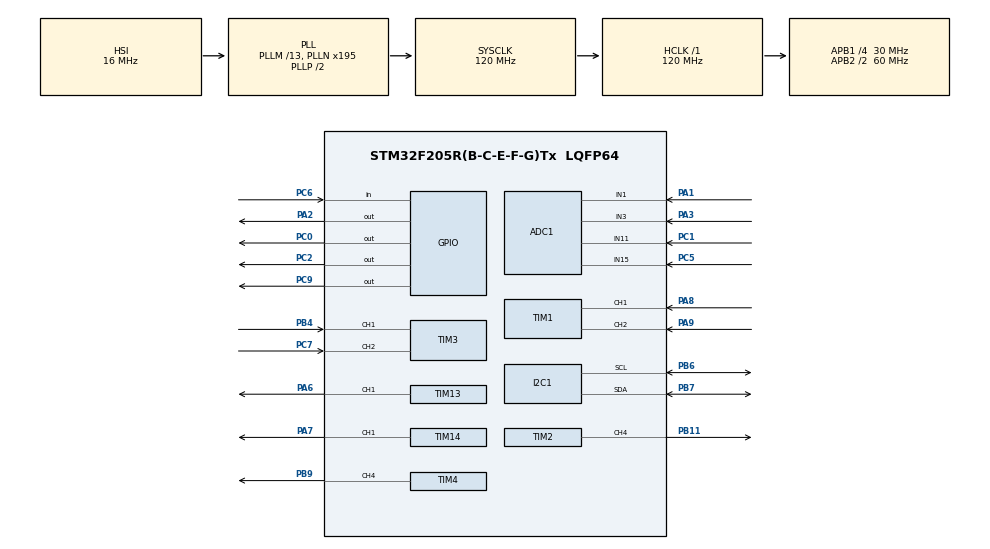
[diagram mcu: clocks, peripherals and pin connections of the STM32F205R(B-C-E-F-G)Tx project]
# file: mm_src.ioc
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ADC1.Channel-0\#ChannelRegularConversion=ADC_CHANNEL_11
ADC1.Channel-1\#ChannelRegularConversion=ADC_CHANNEL_1
ADC1.Channel-2\#ChannelRegularConversion=ADC_CHANNEL_15
ADC1.ContinuousConvMode=ENABLE
ADC1.NbrOfConversion=3
ADC1.NbrOfConversionFlag=1
ADC1.Rank-0\#ChannelRegularConversion=1
ADC1.Rank-1\#ChannelRegularConversion=2
ADC1.Rank-2\#ChannelRegularConversion=3
ADC1.SamplingTime-0\#ChannelRegularConversion=ADC_SAMPLETIME_3CYCLES
ADC1.SamplingTime-1\#ChannelRegularConversion=ADC_SAMPLETIME_3CYCLES
ADC1.SamplingTime-2\#ChannelRegularConversion=ADC_SAMPLETIME_3CYCLES
ADC1.ScanConvMode=ENABLE
ADC1.master=1
Dma.ADC1.0.Direction=DMA_PERIPH_TO_MEMORY
Dma.ADC1.0.FIFOMode=DMA_FIFOMODE_DISABLE
Dma.ADC1.0.Instance=DMA2_Stream0
Dma.ADC1.0.MemDataAlignment=DMA_MDATAALIGN_WORD
Dma.ADC1.0.MemInc=DMA_MINC_ENABLE
Dma.ADC1.0.Mode=DMA_CIRCULAR
Dma.ADC1.0.PeriphDataAlignment=DMA_PDATAALIGN_WORD
Dma.ADC1.0.PeriphInc=DMA_PINC_DISABLE
Dma.ADC1.0.Priority=DMA_PRIORITY_LOW
Dma.Request0=ADC1
Mcu.Family=STM32F2
Mcu.Name=STM32F205R(B-C-E-F-G)Tx
Mcu.Package=LQFP64
NVIC.DMA2_Stream0_IRQn=true\:0\:0\:false\:false\:true\:false\:true\:true
NVIC.PriorityGroup=NVIC_PRIORITYGROUP_4
PA1.Signal=ADCx_IN1
PA13.Mode=Serial_Wire
PA13.Signal=SYS_JTMS-SWDIO
PA14.Mode=Serial_Wire
PA14.Signal=SYS_JTCK-SWCLK
PA2.Signal=GPIO_Output
PA3.Signal=ADCx_IN3
PA6.Signal=S_TIM13_CH1
PA7.Signal=S_TIM14_CH1
PA8.Signal=S_TIM1_CH1
PA9.Signal=S_TIM1_CH2
PB11.Signal=S_TIM2_CH4
PB4.Signal=S_TIM3_CH1
PB6.Mode=I2C
PB6.Signal=I2C1_SCL
PB7.Mode=I2C
PB7.Signal=I2C1_SDA
PB9.Signal=S_TIM4_CH4
PC0.Signal=GPIO_Output
PC1.Signal=ADCx_IN11
PC2.Signal=GPIO_Output
PC5.Signal=ADCx_IN15
PC6.Signal=GPIO_Input
PC7.Signal=S_TIM3_CH2
PC9.Signal=GPIO_Output
PH0-OSC_IN.Mode=HSE-External-Oscillator
PH0-OSC_IN.Signal=RCC_OSC_IN
PH1-OSC_OUT.Mode=HSE-External-Oscillator
PH1-OSC_OUT.Signal=RCC_OSC_OUT
ProjectManager.HeapSize=0x200
ProjectManager.StackSize=0x400
ProjectManager.TargetToolchain=STM32CubeIDE
RCC.48MHZClocksFreq_Value=60000000
RCC.AHBFreq_Value=120000000
RCC.APB1CLKDivider=RCC_HCLK_DIV4
RCC.APB1Freq_Value=30000000
RCC.APB1TimFreq_Value=60000000
RCC.APB2CLKDivider=RCC_HCLK_DIV2
RCC.APB2Freq_Value=60000000
RCC.APB2TimFreq_Value=120000000
RCC.CortexFreq_Value=120000000
RCC.HCLKFreq_Value=120000000
RCC.HSE_VALUE=25000000
RCC.HSI_VALUE=16000000
RCC.LSE_VALUE=32768
RCC.PLLM=13
RCC.PLLN=195
RCC.SYSCLKFreq_VALUE=120000000
RCC.SYSCLKSource=RCC_SYSCLKSOURCE_PLLCLK
RCC.VCOOutputFreq_Value=240000000
SH.ADCx_IN1.0=ADC1_IN1,IN1
SH.ADCx_IN11.0=ADC1_IN11,IN11
SH.ADCx_IN15.0=ADC1_IN15,IN15
SH.ADCx_IN3.0=ADC1_IN3,IN3
SH.S_TIM13_CH1.0=TIM13_CH1,PWM Generation1 CH1
SH.S_TIM14_CH1.0=TIM14_CH1,PWM Generation1 CH1
SH.S_TIM1_CH1.0=TIM1_CH1,Encoder_Interface
SH.S_TIM1_CH2.0=TIM1_CH2,Encoder_Interface
SH.S_TIM2_CH4.0=TIM2_CH4,PWM Generation4 CH4
SH.S_TIM3_CH1.0=TIM3_CH1,Encoder_Interface
SH.S_TIM3_CH2.0=TIM3_CH2,Encoder_Interface
SH.S_TIM4_CH4.0=TIM4_CH4,PWM Generation4 CH4
TIM13.Channel=TIM_CHANNEL_1
TIM13.Period=1000-1
TIM13.Prescaler=120-1
TIM14.Channel=TIM_CHANNEL_1
TIM14.Period=1000-1
TIM14.Prescaler=120-1
TIM2.AutoReloadPreload=TIM_AUTORELOAD_PRELOAD_ENABLE
TIM2.Channel-PWM\ Generation4\ CH4=TIM_CHANNEL_4
TIM2.Period=1000-1
TIM2.Prescaler=120-1
TIM4.AutoReloadPreload=TIM_AUTORELOAD_PRELOAD_ENABLE
TIM4.Channel-PWM\ Generation4\ CH4=TIM_CHANNEL_4
TIM4.Period=1000-1
TIM4.Prescaler=120-1
VP_TIM13_VS_ClockSourceINT.Mode=Enable_Timer
VP_TIM14_VS_ClockSourceINT.Mode=Enable_Timer
board=custom

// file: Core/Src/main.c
/* USER CODE BEGIN Header */
/**
 ******************************************************************************
 * @file           : main.c
 * @brief          : Main program body
 ******************************************************************************
 * @attention
 *
 * Copyright (c) 2026 STMicroelectronics.
 * All rights reserved.
 *
 * This software is licensed under terms that can be found in the LICENSE file
 * in the root directory of this software component.
 * If no LICENSE file comes with this software, it is provided AS-IS.
 *
 ******************************************************************************
 */
/* USER CODE END Header */
#include "main.h"

/* USER CODE BEGIN Includes */
#include <stdlib.h>
#include "stm32f2xx_hal.h"
#include "motors.h"
#include "sensors.h"
#include "global_c.h"
/* USER CODE END Includes */

ADC_HandleTypeDef hadc1;
DMA_HandleTypeDef hdma_adc1;

I2C_HandleTypeDef hi2c1;

TIM_HandleTypeDef htim1;
TIM_HandleTypeDef htim2;
TIM_HandleTypeDef htim3;
TIM_HandleTypeDef htim4;
TIM_HandleTypeDef htim13;
TIM_HandleTypeDef htim14;

void SystemClock_Config(void);
static void MX_GPIO_Init(void);
static void MX_DMA_Init(void);
static void MX_ADC1_Init(void);
static void MX_TIM2_Init(void);
static void MX_TIM3_Init(void);
static void MX_TIM4_Init(void);
static void MX_I2C1_Init(void);
static void MX_TIM1_Init(void);
static void MX_TIM13_Init(void);
static void MX_TIM14_Init(void);

int main(void) {

	/* MCU Configuration--------------------------------------------------------*/

	/* Reset of all peripherals, Initializes the Flash interface and the Systick. */
	HAL_Init();

	/* USER CODE BEGIN Init */
	Motor_Init();
	/* USER CODE END Init */

	/* Configure the system clock */
	SystemClock_Config();

	/* Initialize all configured peripherals */
	MX_GPIO_Init();
	MX_DMA_Init();
	MX_ADC1_Init();
	MX_TIM2_Init();
	MX_TIM3_Init();
	MX_TIM4_Init();
	MX_I2C1_Init();
	MX_TIM1_Init();
	MX_TIM13_Init();
	MX_TIM14_Init();

	/* Infinite loop */
	while (1) {
		IR_EmittersOn();
		HAL_Delay(1);
		// adc_buf gets read by DMA automatically
		IR_EmittersOff();
		HAL_Delay(10);
	}
}

void SystemClock_Config(void) {
	RCC_OscInitTypeDef RCC_OscInitStruct = { 0 };
	RCC_ClkInitTypeDef RCC_ClkInitStruct = { 0 };

	/** Initializes the RCC Oscillators according to the specified parameters
	 * in the RCC_OscInitTypeDef structure.
	 */
	RCC_OscInitStruct.OscillatorType = RCC_OSCILLATORTYPE_HSI;
	RCC_OscInitStruct.HSIState = RCC_HSI_ON;
	RCC_OscInitStruct.HSICalibrationValue = RCC_HSICALIBRATION_DEFAULT;
	RCC_OscInitStruct.PLL.PLLState = RCC_PLL_ON;
	RCC_OscInitStruct.PLL.PLLSource = RCC_PLLSOURCE_HSI;
	RCC_OscInitStruct.PLL.PLLM = 13;
	RCC_OscInitStruct.PLL.PLLN = 195;
	RCC_OscInitStruct.PLL.PLLP = RCC_PLLP_DIV2;
	RCC_OscInitStruct.PLL.PLLQ = 4;
	if (HAL_RCC_OscConfig(&RCC_OscInitStruct) != HAL_OK) {
		Error_Handler();
	}

	/** Initializes the CPU, AHB and APB buses clocks
	 */
	RCC_ClkInitStruct.ClockType = RCC_CLOCKTYPE_HCLK | RCC_CLOCKTYPE_SYSCLK
			| RCC_CLOCKTYPE_PCLK1 | RCC_CLOCKTYPE_PCLK2;
	RCC_ClkInitStruct.SYSCLKSource = RCC_SYSCLKSOURCE_PLLCLK;
	RCC_ClkInitStruct.AHBCLKDivider = RCC_SYSCLK_DIV1;
	RCC_ClkInitStruct.APB1CLKDivider = RCC_HCLK_DIV4;
	RCC_ClkInitStruct.APB2CLKDivider = RCC_HCLK_DIV2;

	if (HAL_RCC_ClockConfig(&RCC_ClkInitStruct, FLASH_LATENCY_3) != HAL_OK) {
		Error_Handler();
	}
}

static void MX_ADC1_Init(void) {

	ADC_ChannelConfTypeDef sConfig = { 0 };

	/** Configure the global features of the ADC (Clock, Resolution, Data Alignment and number of conversion)
	 */
	hadc1.Instance = ADC1;
	hadc1.Init.ClockPrescaler = ADC_CLOCK_SYNC_PCLK_DIV2;
	hadc1.Init.Resolution = ADC_RESOLUTION_12B;
	hadc1.Init.ScanConvMode = ENABLE;
	hadc1.Init.ContinuousConvMode = ENABLE;
	hadc1.Init.DiscontinuousConvMode = DISABLE;
	hadc1.Init.ExternalTrigConvEdge = ADC_EXTERNALTRIGCONVEDGE_NONE;
	hadc1.Init.ExternalTrigConv = ADC_SOFTWARE_START;
	hadc1.Init.DataAlign = ADC_DATAALIGN_RIGHT;
	hadc1.Init.NbrOfConversion = 3;
	hadc1.Init.DMAContinuousRequests = DISABLE;
	hadc1.Init.EOCSelection = ADC_EOC_SINGLE_CONV;
	if (HAL_ADC_Init(&hadc1) != HAL_OK) {
		Error_Handler();
	}

	/** Configure for the selected ADC regular channel its corresponding rank in the sequencer and its sample time.
	 */
	sConfig.Channel = ADC_CHANNEL_11;
	sConfig.Rank = 1;
	sConfig.SamplingTime = ADC_SAMPLETIME_3CYCLES;
	if (HAL_ADC_ConfigChannel(&hadc1, &sConfig) != HAL_OK) {
		Error_Handler();
	}

	/** Configure for the selected ADC regular channel its corresponding rank in the sequencer and its sample time.
	 */
	sConfig.Channel = ADC_CHANNEL_1;
	sConfig.Rank = 2;
	if (HAL_ADC_ConfigChannel(&hadc1, &sConfig) != HAL_OK) {
		Error_Handler();
	}

	/** Configure for the selected ADC regular channel its corresponding rank in the sequencer and its sample time.
	 */
	sConfig.Channel = ADC_CHANNEL_15;
	sConfig.Rank = 3;
	if (HAL_ADC_ConfigChannel(&hadc1, &sConfig) != HAL_OK) {
		Error_Handler();
	}

}

static void MX_I2C1_Init(void) {

	hi2c1.Instance = I2C1;
	hi2c1.Init.ClockSpeed = 100000;
	hi2c1.Init.DutyCycle = I2C_DUTYCYCLE_2;
	hi2c1.Init.OwnAddress1 = 0;
	hi2c1.Init.AddressingMode = I2C_ADDRESSINGMODE_7BIT;
	hi2c1.Init.DualAddressMode = I2C_DUALADDRESS_DISABLE;
	hi2c1.Init.OwnAddress2 = 0;
	hi2c1.Init.GeneralCallMode = I2C_GENERALCALL_DISABLE;
	hi2c1.Init.NoStretchMode = I2C_NOSTRETCH_DISABLE;
	if (HAL_I2C_Init(&hi2c1) != HAL_OK) {
		Error_Handler();
	}

}

static void MX_TIM1_Init(void) {

	TIM_Encoder_InitTypeDef sConfig = { 0 };
	TIM_MasterConfigTypeDef sMasterConfig = { 0 };

	htim1.Instance = TIM1;
	htim1.Init.Prescaler = 0;
	htim1.Init.CounterMode = TIM_COUNTERMODE_UP;
	htim1.Init.Period = 65535;
	htim1.Init.ClockDivision = TIM_CLOCKDIVISION_DIV1;
	htim1.Init.RepetitionCounter = 0;
	htim1.Init.AutoReloadPreload = TIM_AUTORELOAD_PRELOAD_DISABLE;
	sConfig.EncoderMode = TIM_ENCODERMODE_TI1;
	sConfig.IC1Polarity = TIM_ICPOLARITY_RISING;
	sConfig.IC1Selection = TIM_ICSELECTION_DIRECTTI;
	sConfig.IC1Prescaler = TIM_ICPSC_DIV1;
	sConfig.IC1Filter = 0;
	sConfig.IC2Polarity = TIM_ICPOLARITY_RISING;
	sConfig.IC2Selection = TIM_ICSELECTION_DIRECTTI;
	sConfig.IC2Prescaler = TIM_ICPSC_DIV1;
	sConfig.IC2Filter = 0;
	if (HAL_TIM_Encoder_Init(&htim1, &sConfig) != HAL_OK) {
		Error_Handler();
	}
	sMasterConfig.MasterOutputTrigger = TIM_TRGO_RESET;
	sMasterConfig.MasterSlaveMode = TIM_MASTERSLAVEMODE_DISABLE;
	if (HAL_TIMEx_MasterConfigSynchronization(&htim1, &sMasterConfig)
			!= HAL_OK) {
		Error_Handler();
	}

}

static void MX_TIM2_Init(void) {

	TIM_MasterConfigTypeDef sMasterConfig = { 0 };
	TIM_OC_InitTypeDef sConfigOC = { 0 };

	htim2.Instance = TIM2;
	htim2.Init.Prescaler = 120 - 1;
	htim2.Init.CounterMode = TIM_COUNTERMODE_UP;
	htim2.Init.Period = 1000 - 1;
	htim2.Init.ClockDivision = TIM_CLOCKDIVISION_DIV1;
	htim2.Init.AutoReloadPreload = TIM_AUTORELOAD_PRELOAD_ENABLE;
	if (HAL_TIM_PWM_Init(&htim2) != HAL_OK) {
		Error_Handler();
	}
	sMasterConfig.MasterOutputTrigger = TIM_TRGO_RESET;
	sMasterConfig.MasterSlaveMode = TIM_MASTERSLAVEMODE_DISABLE;
	if (HAL_TIMEx_MasterConfigSynchronization(&htim2, &sMasterConfig)
			!= HAL_OK) {
		Error_Handler();
	}
	sConfigOC.OCMode = TIM_OCMODE_PWM1;
	sConfigOC.Pulse = 0;
	sConfigOC.OCPolarity = TIM_OCPOLARITY_HIGH;
	sConfigOC.OCFastMode = TIM_OCFAST_DISABLE;
	if (HAL_TIM_PWM_ConfigChannel(&htim2, &sConfigOC, TIM_CHANNEL_4)
			!= HAL_OK) {
		Error_Handler();
	}
	HAL_TIM_MspPostInit(&htim2);

}

static void MX_TIM3_Init(void) {

	TIM_Encoder_InitTypeDef sConfig = { 0 };
	TIM_MasterConfigTypeDef sMasterConfig = { 0 };

	htim3.Instance = TIM3;
	htim3.Init.Prescaler = 0;
	htim3.Init.CounterMode = TIM_COUNTERMODE_UP;
	htim3.Init.Period = 65535;
	htim3.Init.ClockDivision = TIM_CLOCKDIVISION_DIV1;
	htim3.Init.AutoReloadPreload = TIM_AUTORELOAD_PRELOAD_DISABLE;
	sConfig.EncoderMode = TIM_ENCODERMODE_TI1;
	sConfig.IC1Polarity = TIM_ICPOLARITY_RISING;
	sConfig.IC1Selection = TIM_ICSELECTION_DIRECTTI;
	sConfig.IC1Prescaler = TIM_ICPSC_DIV1;
	sConfig.IC1Filter = 0;
	sConfig.IC2Polarity = TIM_ICPOLARITY_RISING;
	sConfig.IC2Selection = TIM_ICSELECTION_DIRECTTI;
	sConfig.IC2Prescaler = TIM_ICPSC_DIV1;
	sConfig.IC2Filter = 0;
	if (HAL_TIM_Encoder_Init(&htim3, &sConfig) != HAL_OK) {
		Error_Handler();
	}
	sMasterConfig.MasterOutputTrigger = TIM_TRGO_RESET;
	sMasterConfig.MasterSlaveMode = TIM_MASTERSLAVEMODE_DISABLE;
	if (HAL_TIMEx_MasterConfigSynchronization(&htim3, &sMasterConfig)
			!= HAL_OK) {
		Error_Handler();
	}

}

static void MX_TIM4_Init(void) {

	TIM_MasterConfigTypeDef sMasterConfig = { 0 };
	TIM_OC_InitTypeDef sConfigOC = { 0 };

	htim4.Instance = TIM4;
	htim4.Init.Prescaler = 120 - 1;
	htim4.Init.CounterMode = TIM_COUNTERMODE_UP;
	htim4.Init.Period = 1000 - 1;
	htim4.Init.ClockDivision = TIM_CLOCKDIVISION_DIV1;
	htim4.Init.AutoReloadPreload = TIM_AUTORELOAD_PRELOAD_ENABLE;
	if (HAL_TIM_PWM_Init(&htim4) != HAL_OK) {
		Error_Handler();
	}
	sMasterConfig.MasterOutputTrigger = TIM_TRGO_RESET;
	sMasterConfig.MasterSlaveMode = TIM_MASTERSLAVEMODE_DISABLE;
	if (HAL_TIMEx_MasterConfigSynchronization(&htim4, &sMasterConfig)
			!= HAL_OK) {
		Error_Handler();
	}
	sConfigOC.OCMode = TIM_OCMODE_PWM1;
	sConfigOC.Pulse = 0;
	sConfigOC.OCPolarity = TIM_OCPOLARITY_HIGH;
	sConfigOC.OCFastMode = TIM_OCFAST_DISABLE;
	if (HAL_TIM_PWM_ConfigChannel(&htim4, &sConfigOC, TIM_CHANNEL_4)
			!= HAL_OK) {
		Error_Handler();
	}
	HAL_TIM_MspPostInit(&htim4);

}

static void MX_TIM13_Init(void) {

	TIM_OC_InitTypeDef sConfigOC = { 0 };

	htim13.Instance = TIM13;
	htim13.Init.Prescaler = 120 - 1;
	htim13.Init.CounterMode = TIM_COUNTERMODE_UP;
	htim13.Init.Period = 1000 - 1;
	htim13.Init.ClockDivision = TIM_CLOCKDIVISION_DIV1;
	htim13.Init.AutoReloadPreload = TIM_AUTORELOAD_PRELOAD_DISABLE;
	if (HAL_TIM_Base_Init(&htim13) != HAL_OK) {
		Error_Handler();
	}
	if (HAL_TIM_PWM_Init(&htim13) != HAL_OK) {
		Error_Handler();
	}
	sConfigOC.OCMode = TIM_OCMODE_PWM1;
	sConfigOC.Pulse = 0;
	sConfigOC.OCPolarity = TIM_OCPOLARITY_HIGH;
	sConfigOC.OCFastMode = TIM_OCFAST_DISABLE;
	if (HAL_TIM_PWM_ConfigChannel(&htim13, &sConfigOC, TIM_CHANNEL_1)
			!= HAL_OK) {
		Error_Handler();
	}
	HAL_TIM_MspPostInit(&htim13);

}

static void MX_TIM14_Init(void) {

	TIM_OC_InitTypeDef sConfigOC = { 0 };

	htim14.Instance = TIM14;
	htim14.Init.Prescaler = 120 - 1;
	htim14.Init.CounterMode = TIM_COUNTERMODE_UP;
	htim14.Init.Period = 1000 - 1;
	htim14.Init.ClockDivision = TIM_CLOCKDIVISION_DIV1;
	htim14.Init.AutoReloadPreload = TIM_AUTORELOAD_PRELOAD_DISABLE;
	if (HAL_TIM_Base_Init(&htim14) != HAL_OK) {
		Error_Handler();
	}
	if (HAL_TIM_PWM_Init(&htim14) != HAL_OK) {
		Error_Handler();
	}
	sConfigOC.OCMode = TIM_OCMODE_PWM1;
	sConfigOC.Pulse = 0;
	sConfigOC.OCPolarity = TIM_OCPOLARITY_HIGH;
	sConfigOC.OCFastMode = TIM_OCFAST_DISABLE;
	if (HAL_TIM_PWM_ConfigChannel(&htim14, &sConfigOC, TIM_CHANNEL_1)
			!= HAL_OK) {
		Error_Handler();
	}
	HAL_TIM_MspPostInit(&htim14);

}

static void MX_DMA_Init(void) {

	/* DMA controller clock enable */
	__HAL_RCC_DMA2_CLK_ENABLE();

	/* DMA interrupt init */
	/* DMA2_Stream0_IRQn interrupt configuration */
	HAL_NVIC_SetPriority(DMA2_Stream0_IRQn, 0, 0);
	HAL_NVIC_EnableIRQ(DMA2_Stream0_IRQn);

}

static void MX_GPIO_Init(void) {
	GPIO_InitTypeDef GPIO_InitStruct = { 0 };

	/* GPIO Ports Clock Enable */
	__HAL_RCC_GPIOH_CLK_ENABLE();
	__HAL_RCC_GPIOC_CLK_ENABLE();
	__HAL_RCC_GPIOA_CLK_ENABLE();
	__HAL_RCC_GPIOB_CLK_ENABLE();

	/*Configure GPIO pin Output Level */
	HAL_GPIO_WritePin(GPIOC, GPIO_PIN_0 | GPIO_PIN_2 | GPIO_PIN_9,
			GPIO_PIN_RESET);

	/*Configure GPIO pin Output Level */
	HAL_GPIO_WritePin(GPIOA, GPIO_PIN_2, GPIO_PIN_RESET);

	/*Configure GPIO pins : PC0 PC2 PC9 */
	GPIO_InitStruct.Pin = GPIO_PIN_0 | GPIO_PIN_2 | GPIO_PIN_9;
	GPIO_InitStruct.Mode = GPIO_MODE_OUTPUT_PP;
	GPIO_InitStruct.Pull = GPIO_NOPULL;
	GPIO_InitStruct.Speed = GPIO_SPEED_FREQ_LOW;
	HAL_GPIO_Init(GPIOC, &GPIO_InitStruct);

	/*Configure GPIO pin : PA2 */
	GPIO_InitStruct.Pin = GPIO_PIN_2;
	GPIO_InitStruct.Mode = GPIO_MODE_OUTPUT_PP;
	GPIO_InitStruct.Pull = GPIO_NOPULL;
	GPIO_InitStruct.Speed = GPIO_SPEED_FREQ_LOW;
	HAL_GPIO_Init(GPIOA, &GPIO_InitStruct);

	/*Configure GPIO pin : PC6 */
	GPIO_InitStruct.Pin = GPIO_PIN_6;
	GPIO_InitStruct.Mode = GPIO_MODE_INPUT;
	GPIO_InitStruct.Pull = GPIO_NOPULL;
	HAL_GPIO_Init(GPIOC, &GPIO_InitStruct);

}

void Error_Handler(void) {
	__disable_irq();
	while (1) {
	}
}
